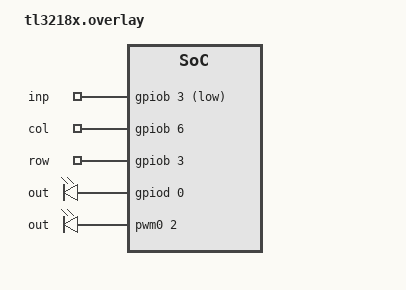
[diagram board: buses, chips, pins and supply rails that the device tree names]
/ {
	/* Short TL_Key3 (J6 pin 21) to ground */
	key_pool {
		compatible = "gpio-keys";

		inp {
			gpios = <&gpiob 3 (GPIO_ACTIVE_LOW | GPIO_PULL_UP)>,
					<&gpiob 5 (GPIO_ACTIVE_LOW | GPIO_PULL_UP)>;
		};
	};

	key_matrix {
		compatible = "gpio-keys";

		col {
			gpios = <&gpiob 6 GPIO_ACTIVE_HIGH>,
					<&gpiob 7 GPIO_ACTIVE_HIGH>;
		};

		row {
			gpios = <&gpiob 3 (GPIO_PULL_DOWN | GPIO_ACTIVE_HIGH)>,
					<&gpiob 5 (GPIO_PULL_DOWN | GPIO_ACTIVE_HIGH)>;
		};
	};

	led_pool {
		compatible = "gpio-leds";

		out {
			gpios = <&gpiod 0 GPIO_ACTIVE_HIGH>;
		};
	};

	pwm_pool {
		compatible = "pwm-leds";
		out {
			pwms = <&pwm0 2 PWM_MSEC(20) PWM_POLARITY_NORMAL>,
					<&pwm0 0 PWM_MSEC(20) PWM_POLARITY_NORMAL>,
					<&pwm0 1 PWM_MSEC(20) PWM_POLARITY_NORMAL>;
		};
	};
};

&pwm0 {
	/* On board RGB LEDs */
	pinctrl-ch0 = <&pwm_ch0_pb1_default>;
	pinctrl-ch2 = <&pwm_ch1_pb2_default>;
	pinctrl-ch1 = <&pwm_ch2_pb0_default>;
};

&pinctrl {
	pwm_ch0_pb1_default: pwm_ch0_pb1_default {
		pinmux = <TLX_PINMUX_SET(TLX_PORT_B, TLX_PIN_1, TL321X_FUNC_PWM0)>;
	};
	pwm_ch1_pb2_default: pwm_ch1_pb2_default {
		pinmux = <TLX_PINMUX_SET(TLX_PORT_B, TLX_PIN_2, TL321X_FUNC_PWM1)>;
	};
	pwm_ch2_pb0_default: pwm_ch2_pb0_default {
		pinmux = <TLX_PINMUX_SET(TLX_PORT_B, TLX_PIN_0, TL321X_FUNC_PWM2)>;
	};
};
